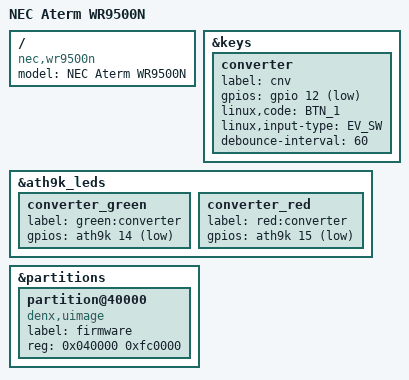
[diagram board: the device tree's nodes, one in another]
// SPDX-License-Identifier: GPL-2.0-or-later OR MIT
/dts-v1/;

#include <dt-bindings/gpio/gpio.h>

#include "ar9344_nec_aterm.dtsi"

/ {
	compatible = "nec,wr9500n", "qca,ar9344";
	model = "NEC Aterm WR9500N";
};

&keys {
	converter {
		label = "cnv";
		gpios = <&gpio 12 GPIO_ACTIVE_LOW>;
		linux,code = <BTN_1>;
		linux,input-type = <EV_SW>;
		debounce-interval = <60>;
	};
};

&ath9k_leds {
	converter_green {
		label = "green:converter";
		gpios = <&ath9k 14 GPIO_ACTIVE_LOW>;
	};

	converter_red {
		label = "red:converter";
		gpios = <&ath9k 15 GPIO_ACTIVE_LOW>;
	};
};

&partitions {
	partition@40000 {
		compatible = "denx,uimage";
		label = "firmware";
		reg = <0x040000 0xfc0000>;
	};
};
